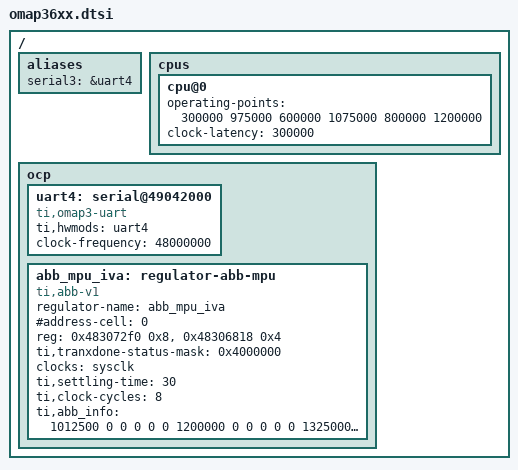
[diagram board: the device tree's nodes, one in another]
/*
 * Device Tree Source for OMAP3 SoC
 *
 * Copyright (C) 2012 Texas Instruments Incorporated - http://www.ti.com/
 *
 * This file is licensed under the terms of the GNU General Public License
 * version 2.  This program is licensed "as is" without any warranty of any
 * kind, whether express or implied.
 */

/include/ "omap3.dtsi"

/ {
	aliases {
		serial3 = &uart4;
	};

	cpus {
		/* OMAP3630/OMAP37xx 'standard device' variants OPP50 to OPP130 */
		cpu@0 {
			operating-points = <
				/* kHz    uV */
				300000   975000
				600000  1075000
				800000  1200000
			>;
			clock-latency = <300000>; /* From legacy driver */
		};
	};

	ocp {
		uart4: serial@49042000 {
			compatible = "ti,omap3-uart";
			ti,hwmods = "uart4";
			clock-frequency = <48000000>;
		};

		abb_mpu_iva: regulator-abb-mpu {
			compatible = "ti,abb-v1";
			regulator-name = "abb_mpu_iva";
			#address-cell = <0>;
			#size-cells = <0>;
			reg = <0x483072f0 0x8>, <0x48306818 0x4>;
			reg-names = "base-address", "int-address";
			ti,tranxdone-status-mask = <0x4000000>;
			clocks = <&sysclk>;
			ti,settling-time = <30>;
			ti,clock-cycles = <8>;
			ti,abb_info = <
			/*uV		ABB	efuse	rbb_m	fbb_m	vset_m*/
			1012500		0	0	0	0	0
			1200000		0	0	0	0	0
			1325000		0	0	0	0	0
			1375000		1	0	0	0	0
			>;
		};
	};
};
